NS_ :

BS_:

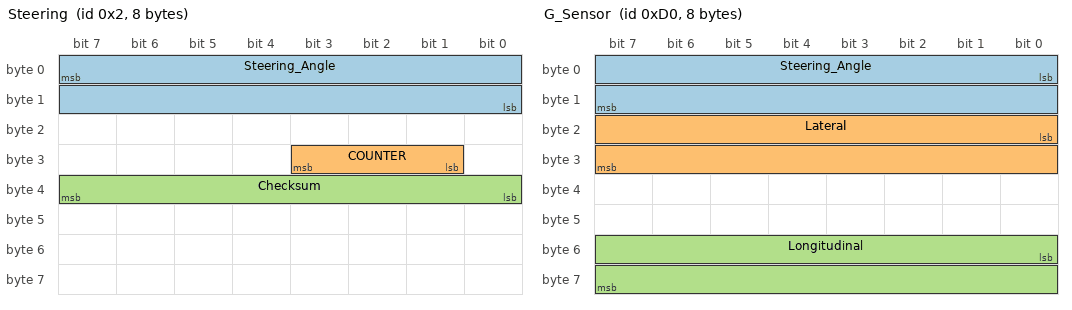
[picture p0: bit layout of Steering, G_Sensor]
BO_ 2 Steering: 8 XXX
 SG_ Steering_Angle : 7|16@0- (0.1,0) [-500|500] "degree" XXX
 SG_ COUNTER : 27|3@0+ (1,0) [0|7] "" XXX
 SG_ Checksum : 39|8@0+ (1,0) [0|255] "" XXX

BO_ 208 G_Sensor: 8 XXX
 SG_ Steering_Angle : 0|16@1- (-0.1,0) [-500|500] "" XXX
 SG_ Lateral : 16|16@1- (-0.0035,1) [-255|255] "" XXX
 SG_ Longitudinal : 48|16@1- (-0.00035,0) [-255|255] "" XXX

BO_ 209 Brake_Pedal: 8 XXX
 SG_ Speed : 0|16@1+ (0.05625,0) [0|255] "KPH" XXX
 SG_ Brake_Pedal : 16|8@1+ (1,0) [0|255] "" XXX

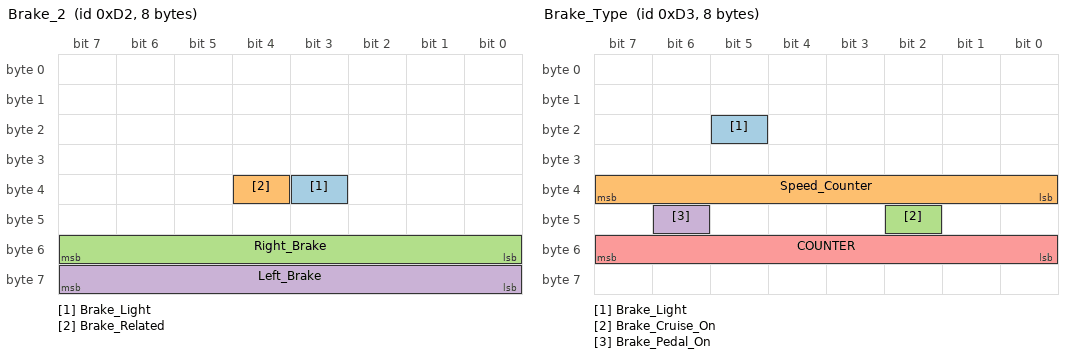
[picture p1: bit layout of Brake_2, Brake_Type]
BO_ 210 Brake_2: 8 XXX
 SG_ Brake_Light : 35|1@1+ (1,0) [0|1] "" XXX
 SG_ Brake_Related : 36|1@1+ (1,0) [0|1] "" XXX
 SG_ Right_Brake : 48|8@1+ (1,0) [0|255] "" XXX
 SG_ Left_Brake : 56|8@1+ (1,0) [0|255] "" XXX

BO_ 211 Brake_Type: 8 XXX
 SG_ Brake_Light : 21|1@1+ (1,0) [0|1] "" XXX
 SG_ Speed_Counter : 32|8@1+ (1,0) [0|255] "" XXX
 SG_ Brake_Cruise_On : 42|1@1+ (1,0) [0|1] "" XXX
 SG_ Brake_Pedal_On : 46|1@1+ (1,0) [0|1] "" XXX
 SG_ COUNTER : 48|8@1+ (1,0) [0|255] "" XXX

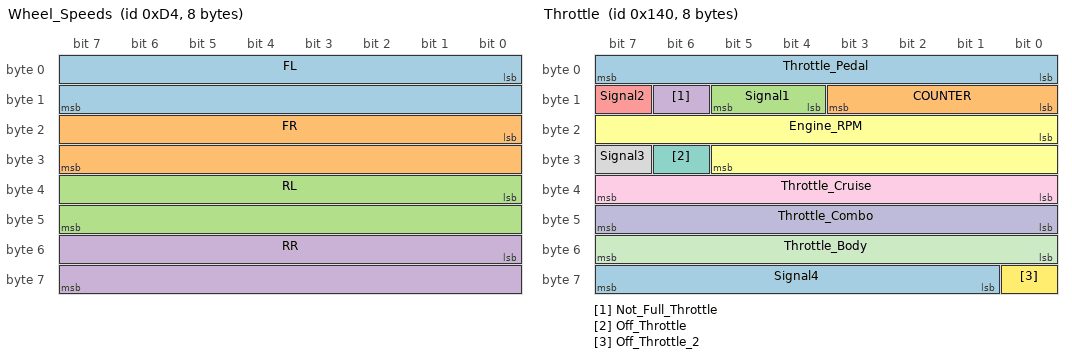
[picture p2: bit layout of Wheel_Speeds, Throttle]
BO_ 212 Wheel_Speeds: 8 XXX
 SG_ FL : 0|16@1+ (0.0592,0) [0|255] "KPH" XXX
 SG_ FR : 16|16@1+ (0.0592,0) [0|255] "KPH" XXX
 SG_ RL : 32|16@1+ (0.0592,0) [0|255] "KPH" XXX
 SG_ RR : 48|16@1+ (0.0592,0) [0|255] "KPH" XXX

BO_ 320 Throttle: 8 XXX
 SG_ Throttle_Pedal : 0|8@1+ (0.392157,0) [0|255] "" XXX
 SG_ COUNTER : 8|4@1+ (1,0) [0|15] "" XXX
 SG_ Signal1 : 12|2@1+ (1,0) [0|7] "" XXX
 SG_ Not_Full_Throttle : 14|1@1+ (1,0) [0|1] "" XXX
 SG_ Signal2 : 15|1@1+ (1,0) [0|1] "" XXX
 SG_ Engine_RPM : 16|14@1+ (1,0) [0|32767] "" XXX
 SG_ Off_Throttle : 30|1@1+ (1,0) [0|1] "" XXX
 SG_ Signal3 : 31|1@1+ (1,0) [0|1] "" XXX
 SG_ Throttle_Cruise : 32|8@1+ (1,0) [0|255] "" XXX
 SG_ Throttle_Combo : 40|8@1+ (1,0) [0|255] "" XXX
 SG_ Throttle_Body : 48|8@1+ (1,0) [0|255] "" XXX
 SG_ Off_Throttle_2 : 56|1@1+ (1,0) [0|1] "" XXX
 SG_ Signal4 : 57|7@1+ (1,0) [0|127] "" XXX

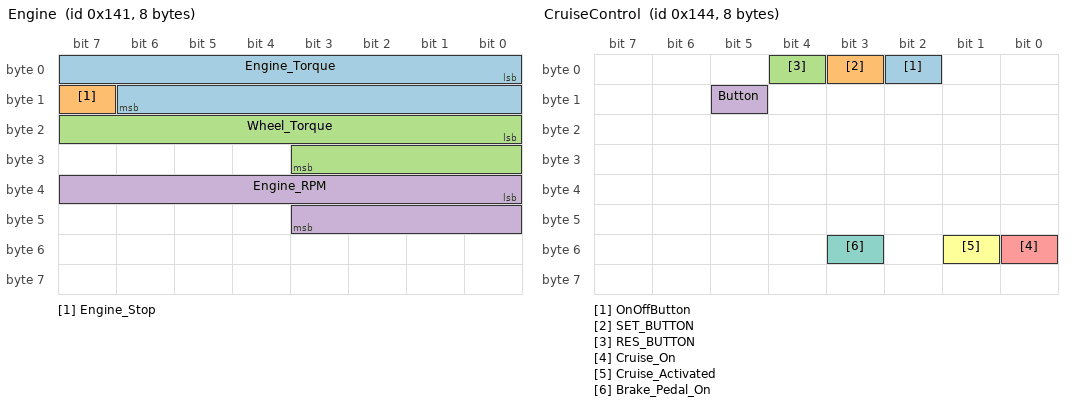
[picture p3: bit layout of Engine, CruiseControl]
BO_ 321 Engine: 8 XXX
 SG_ Engine_Torque : 0|15@1+ (1,0) [0|255] "" XXX
 SG_ Engine_Stop : 15|1@1+ (1,0) [0|1] "" XXX
 SG_ Wheel_Torque : 16|12@1+ (1,0) [0|4095] "" XXX
 SG_ Engine_RPM : 32|12@1+ (1,0) [0|8191] "" XXX

BO_ 324 CruiseControl: 8 XXX
 SG_ OnOffButton : 2|1@1+ (1,0) [0|1] "" XXX
 SG_ SET_BUTTON : 3|1@1+ (1,0) [0|1] "" XXX
 SG_ RES_BUTTON : 4|1@1+ (1,0) [0|1] "" XXX
 SG_ Button : 13|1@1+ (1,0) [0|1] "" XXX
 SG_ Cruise_On : 48|1@1+ (1,0) [0|1] "" XXX
 SG_ Cruise_Activated : 49|1@1+ (1,0) [0|1] "" XXX
 SG_ Brake_Pedal_On : 51|1@1+ (1,0) [0|1] "" XXX

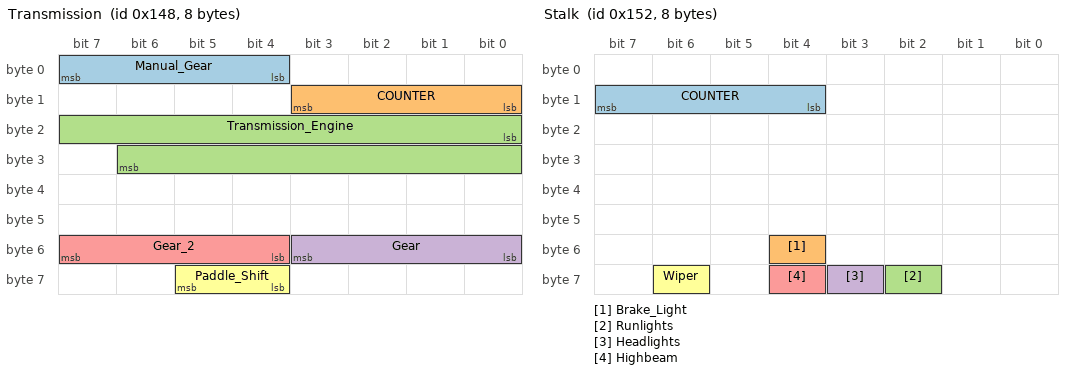
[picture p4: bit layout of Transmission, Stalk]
BO_ 328 Transmission: 8 XXX
 SG_ Manual_Gear : 4|4@1+ (1,0) [0|15] "" XXX
 SG_ COUNTER : 8|4@1+ (1,0) [0|15] "" XXX
 SG_ Transmission_Engine : 16|15@1+ (1,0) [0|65535] "" XXX
 SG_ Gear : 48|4@1+ (1,0) [0|15] "" XXX
 SG_ Gear_2 : 52|4@1+ (1,0) [0|15] "" XXX
 SG_ Paddle_Shift : 60|2@1+ (1,0) [0|3] "" XXX

BO_ 329 CVT_Ratio: 8 XXX

BO_ 336 Brake_Pressure: 8 XXX
 SG_ Brake_Pressure_Right : 0|8@1+ (1,0) [0|255] "" XXX
 SG_ Brake_Pressure_Left : 8|8@1+ (1,0) [0|255] "" XXX

BO_ 338 Stalk: 8 XXX
 SG_ COUNTER : 12|4@1+ (1,0) [0|15] "" XXX
 SG_ Brake_Light : 52|1@1+ (1,0) [0|1] "" XXX
 SG_ Runlights : 58|1@1+ (1,0) [0|1] "" XXX
 SG_ Headlights : 59|1@1+ (1,0) [0|1] "" XXX
 SG_ Highbeam : 60|1@1+ (1,0) [0|1] "" XXX
 SG_ Wiper : 62|1@1+ (1,0) [0|1] "" XXX

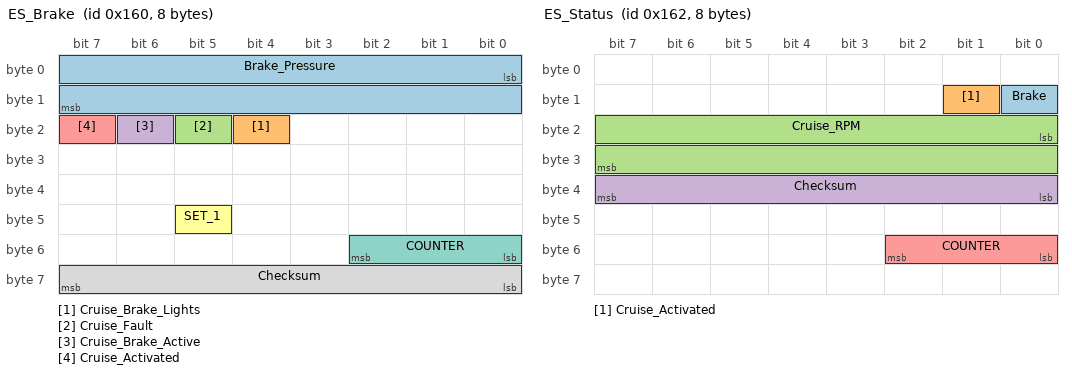
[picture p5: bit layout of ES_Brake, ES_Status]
BO_ 352 ES_Brake: 8 XXX
 SG_ Brake_Pressure : 0|16@1+ (1,0) [0|255] "" XXX
 SG_ Cruise_Brake_Lights : 20|1@1+ (1,0) [0|1] "" XXX
 SG_ Cruise_Fault : 21|1@1+ (1,0) [0|1] "" XXX
 SG_ Cruise_Brake_Active : 22|1@1+ (1,0) [0|1] "" XXX
 SG_ Cruise_Activated : 23|1@1+ (1,0) [0|1] "" XXX
 SG_ SET_1 : 45|1@0+ (1,0) [0|1] "" XXX
 SG_ COUNTER : 48|3@1+ (1,0) [0|7] "" XXX
 SG_ Checksum : 56|8@1+ (1,0) [0|255] "" XXX

BO_ 353 ES_Distance: 8 XXX
 SG_ Cruise_Throttle : 0|12@1+ (1,0) [0|4095] "" XXX
 SG_ Signal1 : 12|4@1+ (1,0) [0|15] "" XXX
 SG_ Car_Follow : 16|1@1+ (1,0) [0|1] "" XXX
 SG_ Signal2 : 17|3@1+ (1,0) [0|7] "" XXX
 SG_ Cruise_Brake_Active : 20|1@1+ (1,0) [0|1] "" XXX
 SG_ Distance_Swap : 21|1@1+ (1,0) [0|1] "" XXX
 SG_ Standstill : 22|1@1+ (1,0) [0|1] "" XXX
 SG_ Signal3 : 23|1@1+ (1,0) [0|1] "" XXX
 SG_ Close_Distance : 24|8@1+ (0.019607,0) [0|5] "m" XXX
 SG_ Signal4 : 32|9@1+ (1,0) [0|255] "" XXX
 SG_ Standstill_2 : 41|1@1+ (1,0) [0|1] "" XXX
 SG_ Cruise_Fault : 42|1@1+ (1,0) [0|1] "" XXX
 SG_ Signal5 : 43|1@1+ (1,0) [0|1] "" XXX
 SG_ COUNTER : 44|3@1+ (1,0) [0|7] "" XXX
 SG_ Signal6 : 47|1@1+ (1,0) [0|1] "" XXX
 SG_ Cruise_Button : 48|3@1+ (1,0) [0|7] "" XXX
 SG_ Signal7 : 51|5@1+ (1,0) [0|31] "" XXX
 SG_ Checksum : 56|8@1+ (1,0) [0|255] "" XXX

BO_ 354 ES_Status: 8 XXX
 SG_ Brake : 8|1@1+ (1,0) [0|1] "" XXX
 SG_ Cruise_Activated : 9|1@1+ (1,0) [0|1] "" XXX
 SG_ Cruise_RPM : 16|16@1+ (1,0) [0|65535] "" XXX
 SG_ Checksum : 32|8@1+ (1,0) [0|255] "" XXX
 SG_ COUNTER : 48|3@1+ (1,0) [0|7] "" XXX

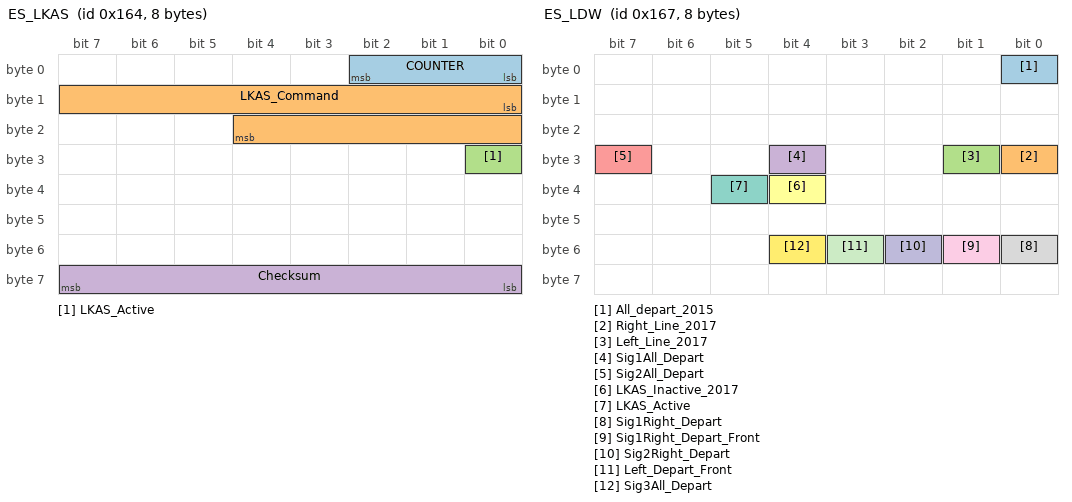
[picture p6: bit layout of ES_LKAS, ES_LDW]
BO_ 356 ES_LKAS: 8 XXX
 SG_ COUNTER : 0|3@1+ (1,0) [0|7] "" XXX
 SG_ LKAS_Command : 8|13@1- (-1,0) [-4096|4096] "" XXX
 SG_ LKAS_Active : 24|1@1+ (1,0) [0|1] "" XXX
 SG_ Checksum : 56|8@1+ (1,0) [0|255] "" XXX

BO_ 359 ES_LDW: 8 XXX
 SG_ All_depart_2015 : 0|1@1+ (1,0) [0|1] "" XXX
 SG_ Right_Line_2017 : 24|1@1+ (1,0) [0|1] "" XXX
 SG_ Left_Line_2017 : 25|1@1+ (1,0) [0|1] "" XXX
 SG_ Sig1All_Depart : 28|1@1+ (1,0) [0|1] "" XXX
 SG_ Sig2All_Depart : 31|1@1+ (1,0) [0|1] "" XXX
 SG_ LKAS_Inactive_2017 : 36|1@1+ (1,0) [0|1] "" XXX
 SG_ LKAS_Active : 37|1@1+ (1,0) [0|1] "" XXX
 SG_ Sig1Right_Depart : 48|1@1+ (1,0) [0|1] "" XXX
 SG_ Sig1Right_Depart_Front : 49|1@1+ (1,0) [0|1] "" XXX
 SG_ Sig2Right_Depart : 50|1@1+ (1,0) [0|1] "" XXX
 SG_ Left_Depart_Front : 51|1@1+ (1,0) [0|1] "" XXX
 SG_ Sig3All_Depart : 52|1@1+ (1,0) [0|1] "" XXX

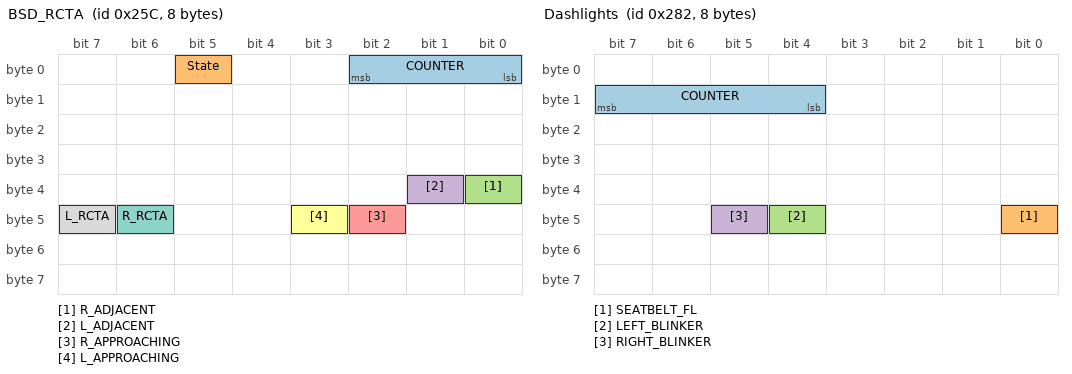
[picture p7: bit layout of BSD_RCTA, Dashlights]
BO_ 604 BSD_RCTA: 8 XXX
 SG_ COUNTER : 0|3@1+ (1,0) [0|7] "" XXX
 SG_ State : 5|1@1+ (1,0) [0|1] "" XXX
 SG_ R_ADJACENT : 32|1@1+ (1,0) [0|1] "" XXX
 SG_ L_ADJACENT : 33|1@1+ (1,0) [0|1] "" XXX
 SG_ R_APPROACHING : 42|1@1+ (1,0) [0|1] "" XXX
 SG_ L_APPROACHING : 43|1@1+ (1,0) [0|1] "" XXX
 SG_ R_RCTA : 46|1@1+ (1,0) [0|1] "" XXX
 SG_ L_RCTA : 47|1@1+ (1,0) [0|1] "" XXX

BO_ 642 Dashlights: 8 XXX
 SG_ COUNTER : 12|4@1+ (1,0) [0|15] "" XXX
 SG_ SEATBELT_FL : 40|1@1+ (1,0) [0|1] "" XXX
 SG_ LEFT_BLINKER : 44|1@1+ (1,0) [0|1] "" XXX
 SG_ RIGHT_BLINKER : 45|1@1+ (1,0) [0|1] "" XXX

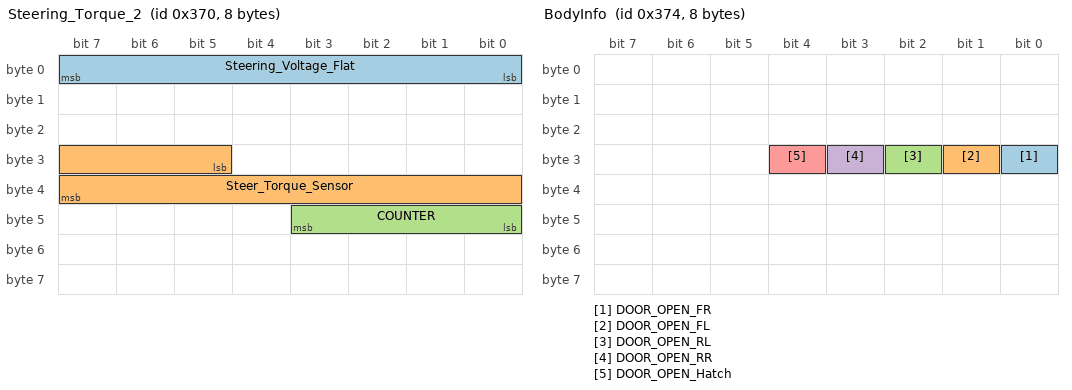
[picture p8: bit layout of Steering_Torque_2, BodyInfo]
BO_ 880 Steering_Torque_2: 8 XXX
 SG_ Steering_Voltage_Flat : 0|8@1+ (1,0) [0|255] "" XXX
 SG_ Steer_Torque_Sensor : 29|11@1- (-1,0) [-1000|1000] "" XXX
 SG_ COUNTER : 40|4@1+ (1,0) [0|15] "" XXX

BO_ 884 BodyInfo: 8 XXX
 SG_ DOOR_OPEN_FR : 24|1@1+ (1,0) [0|1] "" XXX
 SG_ DOOR_OPEN_FL : 25|1@1+ (1,0) [0|1] "" XXX
 SG_ DOOR_OPEN_RL : 26|1@1+ (1,0) [0|1] "" XXX
 SG_ DOOR_OPEN_RR : 27|1@1+ (1,0) [0|1] "" XXX
 SG_ DOOR_OPEN_Hatch : 28|1@1+ (1,0) [0|1] "" XXX

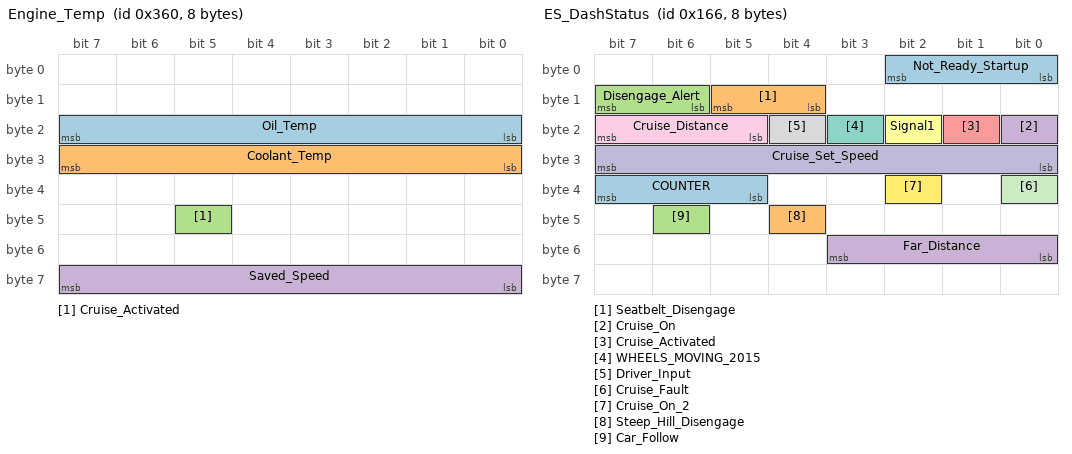
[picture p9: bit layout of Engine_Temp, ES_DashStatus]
BO_ 864 Engine_Temp: 8 XXX
 SG_ Oil_Temp : 16|8@1+ (1,-40) [0|255] "" XXX
 SG_ Coolant_Temp : 24|8@1+ (1,-40) [0|255] "" XXX
 SG_ Cruise_Activated : 45|1@1+ (1,0) [0|1] "" XXX
 SG_ Saved_Speed : 56|8@1+ (1,0) [0|255] "" XXX

BO_ 866 Fuel: 8 XXX

BO_ 977 Dash_State2: 8 XXX
 SG_ UNITS : 15|1@1+ (1,0) [0|1] "" XXX

BO_ 1745 Dash_State: 8 XXX
 SG_ Units : 15|1@1+ (1,0) [0|1] "" XXX

BO_ 358 ES_DashStatus: 8 XXX
 SG_ Not_Ready_Startup : 0|3@1+ (1,0) [0|7] "" XXX
 SG_ Seatbelt_Disengage : 12|2@1+ (1,0) [0|3] "" XXX
 SG_ Disengage_Alert : 14|2@1+ (1,0) [0|3] "" XXX
 SG_ Cruise_On : 16|1@1+ (1,0) [0|1] "" XXX
 SG_ Cruise_Activated : 17|1@1+ (1,0) [0|1] "" XXX
 SG_ Signal1 : 18|1@1+ (1,0) [0|1] "" XXX
 SG_ WHEELS_MOVING_2015 : 19|1@1+ (1,0) [0|1] "" XXX
 SG_ Driver_Input : 20|1@1+ (1,0) [0|1] "" XXX
 SG_ Cruise_Distance : 21|3@1+ (1,0) [0|7] "" XXX
 SG_ Cruise_Set_Speed : 24|8@1+ (1,0) [0|255] "" XXX
 SG_ Cruise_Fault : 32|1@1+ (1,0) [0|1] "" XXX
 SG_ Cruise_On_2 : 34|1@1+ (1,0) [0|1] "" XXX
 SG_ COUNTER : 37|3@1+ (1,0) [0|7] "" XXX
 SG_ Steep_Hill_Disengage : 44|1@1+ (1,0) [0|3] "" XXX
 SG_ Car_Follow : 46|1@1+ (1,0) [0|1] "" XXX
 SG_ Far_Distance : 48|4@1+ (5,0) [0|75] "m" XXX

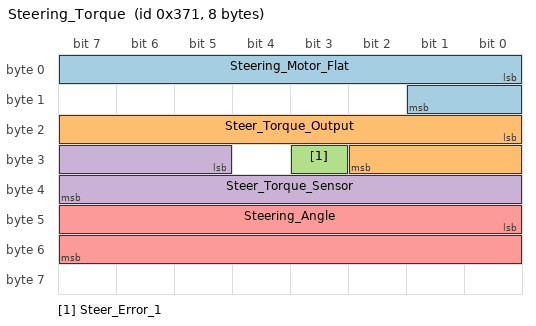
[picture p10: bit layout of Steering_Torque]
BO_ 881 Steering_Torque: 8 XXX
 SG_ Steering_Motor_Flat : 0|10@1+ (32,0) [0|1000] "" XXX
 SG_ Steer_Torque_Output : 16|11@1- (-32,0) [-1000|1000] "" XXX
 SG_ Steer_Error_1 : 27|1@1+ (1,0) [0|1] "" XXX
 SG_ Steer_Torque_Sensor : 29|11@1- (1,0) [-1000|1000] "" XXX
 SG_ Steering_Angle : 40|16@1- (-0.033,0) [-600|600] "" XXX

BU_: XXX

CM_ BU_ K16_BECM "Battery Energy Control Module";
CM_ BU_ K73_TCIC "Telematics Communication Control Module";
CM_ BU_ K9_BCM "Body Control Module";
CM_ BU_ K43_PSCM "Power Steering Control Module";
CM_ BU_ K17_EBCM "Electronic Brake Control Module";
CM_ BU_ K20_ECM "Engine Control Module";
CM_ BU_ K114B_HPCM "Hybrid Powertrain Control Module";
CM_ BU_ NEO "Comma NEO";
CM_ BU_ K124_ASCM "Active Safety Control Module";
CM_ SG_ 381 MSG17D_AccPower "Need to investigate";
CM_ SG_ 190 GasPedalAndAcc "ACC baseline is 62";
CM_ SG_ 451 GasPedalAndAcc2 "ACC baseline is 62";
CM_ SG_ 715 RollingCounter2 "Values cycle between 0, 7, 10, 13";
BA_DEF_  "UseGMParameterIDs" INT 0 0;
BA_DEF_  "ProtocolType" STRING ;
BA_DEF_  "BusType" STRING ;
BA_DEF_DEF_  "UseGMParameterIDs" 1;
BA_DEF_DEF_  "ProtocolType" "GMLAN";
BA_DEF_DEF_  "BusType" "";
BA_ "BusType" "CAN";
BA_ "UseGMParameterIDs" 0;
VAL_ 34 IPMA_PCAN_DataRangeCheck 1 "Fault Present" 0 "No Fault";
VAL_ 34 IPMA_PCAN_MissingMsg 1 "Fault Present" 0 "No Fault ";
VAL_ 34 VINSignalCompareFailure 1 "Fault Present" 0 "No Fault";
VAL_ 34 ModuleNotConfiguredError 1 "Fault Present" 0 "No Fault";
VAL_ 34 CarCfgNotConfiguredError 1 "Fault Present" 0 "No Fault";
VAL_ 33 Active_Flt_Latched_byte7_bit7 1 "Fault Present" 0 "No Fault";
VAL_ 33 Active_Flt_Latched_byte7_bit6 1 "Fault Present" 0 "No Fault";
VAL_ 33 Active_Flt_Latched_byte7_bit5 1 "Fault Present" 0 "No Fault";
VAL_ 33 Active_Flt_Latched_byte7_bit4 1 "Fault Present" 0 "No Fault";
VAL_ 33 ARMtoDSPChksumFault 1 "Fault Present" 0 "No Fault";
VAL_ 33 DSPtoArmChksumFault 1 "Fault Present" 0 "No Fault";
VAL_ 33 HostToArmChksumFault 1 "Fault Present" 0 "No Fault";
VAL_ 33 ARMtoHostChksumFault 1 "Fault Present" 0 "No Fault";
VAL_ 33 LoopBWOutOfRange 1 "Fault Present" 0 "No Fault";
VAL_ 33 DSPOverrunFault 1 "Fault Present" 0 "No Fault";
VAL_ 33 Active_Flt_Latched_byte6_bit5 1 "Fault Present" 0 "No Fault";
VAL_ 33 TuningSensitivityFault 1 "Fault Present" 0 "No Fault";
VAL_ 33 SaturatedTuningFreqFault 1 "Fault Present" 0 "No Fault";
VAL_ 33 LocalOscPowerFault 1 "Fault Present" 0 "No Fault";
VAL_ 33 TransmitterPowerFault 1 "Fault Present" 0 "No Fault";
VAL_ 33 Active_Flt_Latched_byte6_bit0 1 "Fault Present" 0 "No Fault";
VAL_ 33 Active_Flt_Latched_byte5_bit7 1 "Fault Present" 0 "No Fault";
VAL_ 33 Active_Flt_Latched_byte5_bit6 1 "Fault Present" 0 "No Fault";
VAL_ 33 XCVRDeviceSPIFault 1 "Fault Present" 0 "No Fault";
VAL_ 33 FreqSynthesizerSPIFault 1 "Fault Present" 0 "No Fault";
VAL_ 33 AnalogConverterDevicSPIFault 1 "Fault Present" 0 "No Fault";
VAL_ 33 SidelobeBlockage 1 "Fault Present" 0 "No Fault";
VAL_ 33 Active_Flt_Latched_byte5_bit1 1 "Fault Present" 0 "No Fault";
VAL_ 33 MNRBlocked 1 "Fault Present" 0 "No Fault";
VAL_ 33 ECUTempHighFault 1 "Fault Present" 0 "No Fault";
VAL_ 33 TransmitterTempHighFault 1 "Fault Present" 0 "No Fault";
VAL_ 33 AlignmentRoutineFailedFault 1 "Fault Present" 0 "No Fault";
VAL_ 33 UnreasonableRadarData 1 "Fault Present" 0 "No Fault";
VAL_ 33 MicroprocessorTempHighFault 1 "Fault Present" 0 "No Fault";
VAL_ 33 VerticalAlignmentOutOfRange 1 "Fault Present" 0 "No Fault";
VAL_ 33 HorizontalAlignmentOutOfRange 1 "Fault Present" 0 "No Fault";
VAL_ 33 FactoryAlignmentMode 1 "Fault Present" 0 "No Fault";
VAL_ 33 BatteryLowFault 1 "Fault Present" 0 "No Fault";
VAL_ 33 BatteryHighFault 1 "Fault Present" 0 "No Fault";
VAL_ 33 v_1p25SupplyOutOfRange 1 "Fault Present" 0 "No Fault";
VAL_ 33 Active_Flt_Latched_byte3_bit4 1 "Fault Present" 0 "No Fault";
VAL_ 33 ThermistorOutOfRange 1 "Fault Present" 0 "No Fault";
VAL_ 33 v_3p3DACSupplyOutOfRange 1 "Fault Present" 0 "No Fault";
VAL_ 33 v_3p3RAWSupplyOutOfRange 1 "Fault Present" 0 "No Fault";
VAL_ 33 v_5_SupplyOutOfRange 1 "Fault Present" 0 "No Fault";
VAL_ 33 TransmitterIDFault 1 "Fault Present" 0 "No Fault";
VAL_ 33 Active_Flt_Latched_byte2_bit6 1 "Fault Present" 0 "No Fault";
VAL_ 33 Active_Flt_Latched_byte2_bit5 1 "Fault Present" 0 "No Fault";
VAL_ 33 Active_Flt_Latched_byte2_bit4 1 "Fault Present" 0 "No Fault";
VAL_ 33 Active_Flt_Latched_byte2_bit3 1 "Fault Present" 0 "No Fault";
VAL_ 33 Active_Flt_Latched_byte2_bit2 1 "Fault Present" 0 "No Fault";
VAL_ 33 PCANMissingMsgFault 1 "Fault Present" 0 "No Fault";
VAL_ 33 PCANBusOff 1 "Fault Present" 0 "No Fault";
VAL_ 33 Active_Flt_Latched_byte1_bit7 1 "Fault Present" 0 "No Fault";
VAL_ 33 Active_Flt_Latched_byte1_bit6 1 "Fault Present" 0 "No Fault";
VAL_ 33 InstructionSetCheckFault 1 "Fault Present" 0 "No Fault";
VAL_ 33 StackOverflowFault 1 "Fault Present" 0 "No Fault";
VAL_ 33 WatchdogFault 1 "Fault Present" 0 "No Fault";
VAL_ 33 PLLLockFault 1 "Fault Present" 0 "No Fault";
VAL_ 33 Active_Flt_Latched_byte1_bit1 1 "Fault Present" 0 "No Fault";
VAL_ 33 RAMMemoryTestFault 1 "Fault Present" 0 "No Fault";
VAL_ 33 USCValidationFault 1 "Fault Present" 0 "No Fault";
VAL_ 33 Active_Flt_Latched_byte0_bit6 1 "Fault Present" 0 "No Fault";
VAL_ 33 Active_Flt_Latched_byte0_bit5 1 "Fault Present" 0 "No Fault";
VAL_ 33 Active_Flt_Latched_byte0_bit4 1 "Fault Present" 0 "No Fault";
VAL_ 33 Active_Flt_Latched_byte0_bit3 1 "Fault Present" 0 "No Fault";
VAL_ 33 KeepAliveChecksumFault 1 "Fault Present" 0 "No Fault";
VAL_ 33 ProgramCalibrationFlashChecksum 1 "Fault Present" 0 "No Fault";
VAL_ 33 ApplicationFlashChecksumFault 1 "Fault Present" 0 "No Fault";
VAL_ 371 CAN_AUTO_ALIGN_HANGLE_QF 3 "Accurate" 2 "Innacurate" 1 "Temporarily undefined" 0 "Undefined";
VAL_ 371 CAN_ALIGNMENT_STATUS 15 "Undefined_2" 14 "Undefined_1" 13 "Low Amplitude (Flat-plate only)" 12 "No Peak (Flat-plate only)" 11 "Fail Ver and Hor OutOfRange" 10 "Fail Vertical Align OutOfRange" 9 "Fail Horizontal Align OutOfRange" 8 "Fail Time Out" 7 "Fail Only Right Target Found" 6 "Fail Only Left Target Found" 5 "Fail Variance Too Large" 4 "Fail Deviation Too Large" 3 "Fail No Target" 2 "Success" 1 "Busy" 0 "Off";
VAL_ 371 CAN_ALIGNMENT_STATE 6 "Static alignment flat-plate" 5 "Static alignment 2-target" 4 "Static alignment 1-target" 3 "Service alignment" 2 "Short track alignment" 1 "Auto alignment" 0 "Off";
VAL_ 291 CAN_DET_CONFID_AZIMUTH_04 3 "Low" 2 "Medium_Low" 1 "Medium_High" 0 "High";
VAL_ 351 CAN_DET_CONFID_AZIMUTH_64 3 "Low" 2 "Medium_Low" 1 "Medium_High" 0 "High";
VAL_ 350 CAN_DET_CONFID_AZIMUTH_63 3 "Low" 2 "Medium_Low" 1 "Medium_High" 0 "High";
VAL_ 349 CAN_DET_CONFID_AZIMUTH_62 3 "Low" 2 "Medium_Low" 1 "Medium_High" 0 "High";
VAL_ 348 CAN_DET_CONFID_AZIMUTH_61 3 "Low" 2 "Medium_Low" 1 "Medium_High" 0 "High";
VAL_ 347 CAN_DET_CONFID_AZIMUTH_60 3 "Low" 2 "Medium_Low" 1 "Medium_High" 0 "High";
VAL_ 346 CAN_DET_CONFID_AZIMUTH_59 3 "Low" 2 "Medium_Low" 1 "Medium_High" 0 "High";
VAL_ 345 CAN_DET_CONFID_AZIMUTH_58 3 "Low" 2 "Medium_Low" 1 "Medium_High" 0 "High";
VAL_ 344 CAN_DET_CONFID_AZIMUTH_57 3 "Low" 2 "Medium_Low" 1 "Medium_High" 0 "High";
VAL_ 343 CAN_DET_CONFID_AZIMUTH_56 3 "Low" 2 "Medium_Low" 1 "Medium_High" 0 "High";
VAL_ 342 CAN_DET_CONFID_AZIMUTH_55 3 "Low" 2 "Medium_Low" 1 "Medium_High" 0 "High";
VAL_ 335 CAN_DET_CONFID_AZIMUTH_48 3 "Low" 2 "Medium_Low" 1 "Medium_High" 0 "High";
VAL_ 334 CAN_DET_CONFID_AZIMUTH_47 3 "Low" 2 "Medium_Low" 1 "Medium_High" 0 "High";
VAL_ 333 CAN_DET_CONFID_AZIMUTH_46 3 "Low" 2 "Medium_Low" 1 "Medium_High" 0 "High";
VAL_ 332 CAN_DET_CONFID_AZIMUTH_45 3 "Low" 2 "Medium_Low" 1 "Medium_High" 0 "High";
VAL_ 331 CAN_DET_CONFID_AZIMUTH_44 3 "Low" 2 "Medium_Low" 1 "Medium_High" 0 "High";
VAL_ 330 CAN_DET_CONFID_AZIMUTH_43 3 "Low" 2 "Medium_Low" 1 "Medium_High" 0 "High";
VAL_ 329 CAN_DET_CONFID_AZIMUTH_42 3 "Low" 2 "Medium_Low" 1 "Medium_High" 0 "High";
VAL_ 328 CAN_DET_CONFID_AZIMUTH_41 3 "Low" 2 "Medium_Low" 1 "Medium_High" 0 "High";
VAL_ 327 CAN_DET_CONFID_AZIMUTH_40 3 "Low" 2 "Medium_Low" 1 "Medium_High" 0 "High";
VAL_ 325 CAN_DET_CONFID_AZIMUTH_38 3 "Low" 2 "Medium_Low" 1 "Medium_High" 0 "High";
VAL_ 324 CAN_DET_CONFID_AZIMUTH_37 3 "Low" 2 "Medium_Low" 1 "Medium_High" 0 "High";
VAL_ 323 CAN_DET_CONFID_AZIMUTH_36 3 "Low" 2 "Medium_Low" 1 "Medium_High" 0 "High";
VAL_ 322 CAN_DET_CONFID_AZIMUTH_35 3 "Low" 2 "Medium_Low" 1 "Medium_High" 0 "High";
VAL_ 321 CAN_DET_CONFID_AZIMUTH_34 3 "Low" 2 "Medium_Low" 1 "Medium_High" 0 "High";
VAL_ 320 CAN_DET_CONFID_AZIMUTH_33 3 "Low" 2 "Medium_Low" 1 "Medium_High" 0 "High";
VAL_ 319 CAN_DET_CONFID_AZIMUTH_32 3 "Low" 2 "Medium_Low" 1 "Medium_High" 0 "High";
VAL_ 318 CAN_DET_CONFID_AZIMUTH_31 3 "Low" 2 "Medium_Low" 1 "Medium_High" 0 "High";
VAL_ 317 CAN_DET_CONFID_AZIMUTH_30 3 "Low" 2 "Medium_Low" 1 "Medium_High" 0 "High";
VAL_ 316 CAN_DET_CONFID_AZIMUTH_29 3 "Low" 2 "Medium_Low" 1 "Medium_High" 0 "High";
VAL_ 314 CAN_DET_CONFID_AZIMUTH_27 3 "Low" 2 "Medium_Low" 1 "Medium_High" 0 "High";
VAL_ 313 CAN_DET_CONFID_AZIMUTH_26 3 "Low" 2 "Medium_Low" 1 "Medium_High" 0 "High";
VAL_ 312 CAN_DET_CONFID_AZIMUTH_25 3 "Low" 2 "Medium_Low" 1 "Medium_High" 0 "High";
VAL_ 311 CAN_DET_CONFID_AZIMUTH_24 3 "Low" 2 "Medium_Low" 1 "Medium_High" 0 "High";
VAL_ 310 CAN_DET_CONFID_AZIMUTH_23 3 "Low" 2 "Medium_Low" 1 "Medium_High" 0 "High";
VAL_ 309 CAN_DET_CONFID_AZIMUTH_22 3 "Low" 2 "Medium_Low" 1 "Medium_High" 0 "High";
VAL_ 308 CAN_DET_CONFID_AZIMUTH_21 3 "Low" 2 "Medium_Low" 1 "Medium_High" 0 "High";
VAL_ 307 CAN_DET_CONFID_AZIMUTH_20 3 "Low" 2 "Medium_Low" 1 "Medium_High" 0 "High";
VAL_ 306 CAN_DET_CONFID_AZIMUTH_19 3 "Low" 2 "Medium_Low" 1 "Medium_High" 0 "High";
VAL_ 305 CAN_DET_CONFID_AZIMUTH_18 3 "Low" 2 "Medium_Low" 1 "Medium_High" 0 "High";
VAL_ 341 CAN_DET_CONFID_AZIMUTH_54 3 "Low" 2 "Medium_Low" 1 "Medium_High" 0 "High";
VAL_ 340 CAN_DET_CONFID_AZIMUTH_53 3 "Low" 2 "Medium_Low" 1 "Medium_High" 0 "High";
VAL_ 339 CAN_DET_CONFID_AZIMUTH_52 3 "Low" 2 "Medium_Low" 1 "Medium_High" 0 "High";
VAL_ 338 CAN_DET_CONFID_AZIMUTH_51 3 "Low" 2 "Medium_Low" 1 "Medium_High" 0 "High";
VAL_ 337 CAN_DET_CONFID_AZIMUTH_50 3 "Low" 2 "Medium_Low" 1 "Medium_High" 0 "High";
VAL_ 336 CAN_DET_CONFID_AZIMUTH_49 3 "Low" 2 "Medium_Low" 1 "Medium_High" 0 "High";
VAL_ 326 CAN_DET_CONFID_AZIMUTH_39 3 "Low" 2 "Medium_Low" 1 "Medium_High" 0 "High";
VAL_ 315 CAN_DET_CONFID_AZIMUTH_28 3 "Low" 2 "Medium_Low" 1 "Medium_High" 0 "High";
VAL_ 304 CAN_DET_CONFID_AZIMUTH_17 3 "Low" 2 "Medium_Low" 1 "Medium_High" 0 "High";
VAL_ 303 CAN_DET_CONFID_AZIMUTH_16 3 "Low" 2 "Medium_Low" 1 "Medium_High" 0 "High";
VAL_ 302 CAN_DET_CONFID_AZIMUTH_15 3 "Low" 2 "Medium_Low" 1 "Medium_High" 0 "High";
VAL_ 301 CAN_DET_CONFID_AZIMUTH_14 3 "Low" 2 "Medium_Low" 1 "Medium_High" 0 "High";
VAL_ 300 CAN_DET_CONFID_AZIMUTH_13 3 "Low" 2 "Medium_Low" 1 "Medium_High" 0 "High";
VAL_ 299 CAN_DET_CONFID_AZIMUTH_12 3 "Low" 2 "Medium_Low" 1 "Medium_High" 0 "High";
VAL_ 298 CAN_DET_CONFID_AZIMUTH_11 3 "Low" 2 "Medium_Low" 1 "Medium_High" 0 "High";
VAL_ 297 CAN_DET_CONFID_AZIMUTH_10 3 "Low" 2 "Medium_Low" 1 "Medium_High" 0 "High";
VAL_ 296 CAN_DET_CONFID_AZIMUTH_09 3 "Low" 2 "Medium_Low" 1 "Medium_High" 0 "High";
VAL_ 295 CAN_DET_CONFID_AZIMUTH_08 3 "Low" 2 "Medium_Low" 1 "Medium_High" 0 "High";
VAL_ 294 CAN_DET_CONFID_AZIMUTH_07 3 "Low" 2 "Medium_Low" 1 "Medium_High" 0 "High";
VAL_ 293 CAN_DET_CONFID_AZIMUTH_06 3 "Low" 2 "Medium_Low" 1 "Medium_High" 0 "High";
VAL_ 292 CAN_DET_CONFID_AZIMUTH_05 3 "Low" 2 "Medium_Low" 1 "Medium_High" 0 "High";
VAL_ 290 CAN_DET_CONFID_AZIMUTH_03 3 "Low" 2 "Medium_Low" 1 "Medium_High" 0 "High";
VAL_ 289 CAN_DET_CONFID_AZIMUTH_02 3 "Low" 2 "Medium_Low" 1 "Medium_High" 0 "High";
VAL_ 257 CAN_INTERFERENCE_TYPE 2 "Star PD-Like" 1 "Slow FMCW" 0 "No Interference";
VAL_ 257 CAN_RECOMMEND_UNCONVERGE 1 "Recommended" 0 "Not Recommended";
VAL_ 257 CAN_RADAR_ALIGN_INCOMPLETE 1 "Alignment Incomplete" 0 "Alignment Completed";
VAL_ 257 CAN_BLOCKAGE_SIDELOBE 1 "Radar Blockage" 0 "No Radar Blockage";
VAL_ 257 CAN_BLOCKAGE_MNR 1 "Radar Blockage" 0 "No Radar Blockage";
VAL_ 257 CAN_RADAR_EXT_COND_NOK 1 "Too high temp or insufficient pw" 0 "External conditions OK";
VAL_ 257 CAN_RADAR_ALIGN_OUT_RANGE 1 "Radar out of range" 0 "Radar within range";
VAL_ 257 CAN_RADAR_ALIGN_NOT_START 1 "Radar align not started" 0 "Radar align started";
VAL_ 257 CAN_RADAR_OVERHEAT_ERROR 1 "Radar overheat condition" 0 "No Overheat";
VAL_ 257 CAN_RADAR_NOT_OP 1 "Radar not operational" 0 "Radar operational";
VAL_ 257 CAN_XCVR_OPERATIONAL 1 "On" 0 "Off ";
